AUTOSAR XML (schema 3.1.2)
package /Components/SWC_AdvMinT
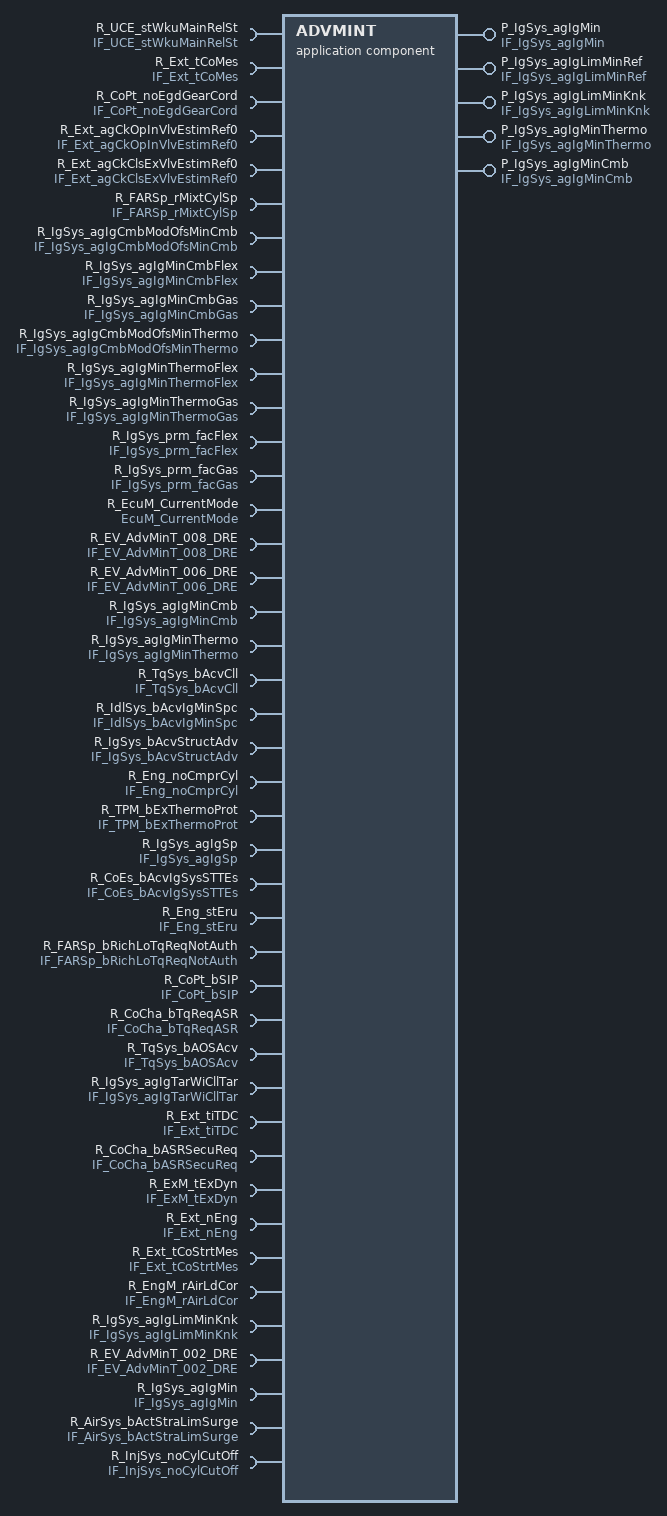
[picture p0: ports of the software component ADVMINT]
  application software component type ADVMINT  # AdvMinT
    require port R_UCE_stWkuMainRelSt: required-interface=IF_UCE_stWkuMainRelSt
    5 x provide port:
      P_IgSys_agIgMin: unqueued-sender-com-spec{data-element=IgSys_agIgMin, can-invalidate=false, init-value=ConstantValue}, provided-interface=IF_IgSys_agIgMin
      P_IgSys_agIgLimMinRef: unqueued-sender-com-spec{data-element=IgSys_agIgLimMinRef, can-invalidate=false, init-value=UInt8InitValue}, provided-interface=IF_IgSys_agIgLimMinRef
      P_IgSys_agIgLimMinKnk: unqueued-sender-com-spec{data-element=IgSys_agIgLimMinKnk, can-invalidate=false, init-value=UInt8InitValue1}, provided-interface=IF_IgSys_agIgLimMinKnk
      P_IgSys_agIgMinThermo: unqueued-sender-com-spec{data-element=IgSys_agIgMinThermo, can-invalidate=false, init-value=UInt8InitValue3}, provided-interface=IF_IgSys_agIgMinThermo
      P_IgSys_agIgMinCmb: unqueued-sender-com-spec{data-element=IgSys_agIgMinCmb, can-invalidate=false, init-value=UInt8InitValue5}, provided-interface=IF_IgSys_agIgMinCmb
    42 x require port:
      R_Ext_tCoMes: unqueued-receiver-com-spec{data-element=Ext_tCoMes, init-value=ConstantValue7, resync-time=0}, required-interface=IF_Ext_tCoMes
      R_CoPt_noEgdGearCord: unqueued-receiver-com-spec{data-element=CoPt_noEgdGearCord, init-value=ConstantValue9, resync-time=0}, required-interface=IF_CoPt_noEgdGearCord
      R_Ext_agCkOpInVlvEstimRef0: unqueued-receiver-com-spec{data-element=Ext_agCkOpInVlvEstimRef0, init-value=ConstantValue11, resync-time=0}, required-interface=IF_Ext_agCkOpInVlvEstimRef0
      R_Ext_agCkClsExVlvEstimRef0: unqueued-receiver-com-spec{data-element=Ext_agCkClsExVlvEstimRef0, init-value=ConstantValue13, resync-time=0}, required-interface=IF_Ext_agCkClsExVlvEstimRef0
      R_FARSp_rMixtCylSp: unqueued-receiver-com-spec{data-element=FARSp_rMixtCylSp, init-value=ConstantValue15, resync-time=0}, required-interface=IF_FARSp_rMixtCylSp
      R_IgSys_agIgCmbModOfsMinCmb: unqueued-receiver-com-spec{data-element=IgSys_agIgCmbModOfsMinCmb, init-value=SInt16InitValue, resync-time=0}, required-interface=IF_IgSys_agIgCmbModOfsMinCmb
      R_IgSys_agIgMinCmbFlex: unqueued-receiver-com-spec{data-element=IgSys_agIgMinCmbFlex, init-value=SInt16InitValue17, resync-time=0}, required-interface=IF_IgSys_agIgMinCmbFlex
      R_IgSys_agIgMinCmbGas: unqueued-receiver-com-spec{data-element=IgSys_agIgMinCmbGas, init-value=SInt16InitValue19, resync-time=0}, required-interface=IF_IgSys_agIgMinCmbGas
      R_IgSys_agIgCmbModOfsMinThermo: unqueued-receiver-com-spec{data-element=IgSys_agIgCmbModOfsMinThermo, init-value=SInt16InitValue21, resync-time=0}, required-interface=IF_IgSys_agIgCmbModOfsMinThermo
      R_IgSys_agIgMinThermoFlex: unqueued-receiver-com-spec{data-element=IgSys_agIgMinThermoFlex, init-value=SInt16InitValue23, resync-time=0}, required-interface=IF_IgSys_agIgMinThermoFlex
      R_IgSys_agIgMinThermoGas: unqueued-receiver-com-spec{data-element=IgSys_agIgMinThermoGas, init-value=SInt16InitValue25, resync-time=0}, required-interface=IF_IgSys_agIgMinThermoGas
      R_IgSys_prm_facFlex: unqueued-receiver-com-spec{data-element=IgSys_prm_facFlex, init-value=ArrayConstantValue, resync-time=0}, required-interface=IF_IgSys_prm_facFlex
      R_IgSys_prm_facGas: unqueued-receiver-com-spec{data-element=IgSys_prm_facGas, init-value=ArrayConstantValue27, resync-time=0}, required-interface=IF_IgSys_prm_facGas
      R_EcuM_CurrentMode: required-interface=EcuM_CurrentMode
      R_EV_AdvMinT_008_DRE: unqueued-receiver-com-spec{data-element=EV_AdvMinT_008_DRE, init-value=UInt8InitValue29, resync-time=0}, required-interface=IF_EV_AdvMinT_008_DRE
      R_EV_AdvMinT_006_DRE: unqueued-receiver-com-spec{data-element=EV_AdvMinT_006_DRE, init-value=UInt8InitValue31, resync-time=0}, required-interface=IF_EV_AdvMinT_006_DRE
      R_IgSys_agIgMinCmb: unqueued-receiver-com-spec{data-element=IgSys_agIgMinCmb, init-value=UInt8InitValue33, resync-time=0}, required-interface=IF_IgSys_agIgMinCmb
      R_IgSys_agIgMinThermo: unqueued-receiver-com-spec{data-element=IgSys_agIgMinThermo, init-value=UInt8InitValue35, resync-time=0}, required-interface=IF_IgSys_agIgMinThermo
      R_TqSys_bAcvCll: unqueued-receiver-com-spec{data-element=TqSys_bAcvCll, init-value=BooleanInitValue, resync-time=0}, required-interface=IF_TqSys_bAcvCll
      R_IdlSys_bAcvIgMinSpc: unqueued-receiver-com-spec{data-element=IdlSys_bAcvIgMinSpc, init-value=BooleanInitValue37, resync-time=0}, required-interface=IF_IdlSys_bAcvIgMinSpc
      R_IgSys_bAcvStructAdv: unqueued-receiver-com-spec{data-element=IgSys_bAcvStructAdv, init-value=ConstantValue39, resync-time=0}, required-interface=IF_IgSys_bAcvStructAdv
      R_Eng_noCmprCyl: unqueued-receiver-com-spec{data-element=Eng_noCmprCyl, init-value=ConstantValue41, resync-time=0}, required-interface=IF_Eng_noCmprCyl
      R_TPM_bExThermoProt: unqueued-receiver-com-spec{data-element=TPM_bExThermoProt, init-value=BooleanInitValue43, resync-time=0}, required-interface=IF_TPM_bExThermoProt
      R_IgSys_agIgSp: unqueued-receiver-com-spec{data-element=IgSys_agIgSp, init-value=ConstantValue45, resync-time=0}, required-interface=IF_IgSys_agIgSp
      R_CoEs_bAcvIgSysSTTEs: unqueued-receiver-com-spec{data-element=CoEs_bAcvIgSysSTTEs, init-value=ConstantValue47, resync-time=0}, required-interface=IF_CoEs_bAcvIgSysSTTEs
      R_Eng_stEru: unqueued-receiver-com-spec{data-element=Eng_stEru, init-value=ConstantValue49, resync-time=0}, required-interface=IF_Eng_stEru
      R_FARSp_bRichLoTqReqNotAuth: unqueued-receiver-com-spec{data-element=FARSp_bRichLoTqReqNotAuth, init-value=BooleanInitValue51, resync-time=0}, required-interface=IF_FARSp_bRichLoTqReqNotAuth
      R_CoPt_bSIP: unqueued-receiver-com-spec{data-element=CoPt_bSIP, init-value=BooleanInitValue53, resync-time=0}, required-interface=IF_CoPt_bSIP
      R_CoCha_bTqReqASR: unqueued-receiver-com-spec{data-element=CoCha_bTqReqASR, init-value=BooleanInitValue55, resync-time=0}, required-interface=IF_CoCha_bTqReqASR
      R_TqSys_bAOSAcv: unqueued-receiver-com-spec{data-element=TqSys_bAOSAcv, init-value=BooleanInitValue57, resync-time=0}, required-interface=IF_TqSys_bAOSAcv
      R_IgSys_agIgTarWiCllTar: unqueued-receiver-com-spec{data-element=IgSys_agIgTarWiCllTar, init-value=ConstantValue59, resync-time=0}, required-interface=IF_IgSys_agIgTarWiCllTar
      R_Ext_tiTDC: unqueued-receiver-com-spec{data-element=Ext_tiTDC, init-value=ConstantValue61, resync-time=0}, required-interface=IF_Ext_tiTDC
      R_CoCha_bASRSecuReq: unqueued-receiver-com-spec{data-element=CoCha_bASRSecuReq, init-value=BooleanInitValue63, resync-time=0}, required-interface=IF_CoCha_bASRSecuReq
      R_ExM_tExDyn: unqueued-receiver-com-spec{data-element=ExM_tExDyn, init-value=UInt16InitValue, resync-time=0}, required-interface=IF_ExM_tExDyn
      R_Ext_nEng: unqueued-receiver-com-spec{data-element=Ext_nEng, init-value=ConstantValue65, resync-time=0}, required-interface=IF_Ext_nEng
      R_Ext_tCoStrtMes: unqueued-receiver-com-spec{data-element=Ext_tCoStrtMes, init-value=SInt16InitValue67, resync-time=0}, required-interface=IF_Ext_tCoStrtMes
      R_EngM_rAirLdCor: unqueued-receiver-com-spec{data-element=EngM_rAirLdCor, init-value=ConstantValue69, resync-time=0}, required-interface=IF_EngM_rAirLdCor
      R_IgSys_agIgLimMinKnk: unqueued-receiver-com-spec{data-element=IgSys_agIgLimMinKnk, init-value=UInt8InitValue71, resync-time=0}, required-interface=IF_IgSys_agIgLimMinKnk
      R_EV_AdvMinT_002_DRE: unqueued-receiver-com-spec{data-element=EV_AdvMinT_002_DRE, init-value=UInt8InitValue73, resync-time=0}, required-interface=IF_EV_AdvMinT_002_DRE
      R_IgSys_agIgMin: unqueued-receiver-com-spec{data-element=IgSys_agIgMin, init-value=ConstantValue, resync-time=0}, required-interface=IF_IgSys_agIgMin
      R_AirSys_bActStraLimSurge: unqueued-receiver-com-spec{data-element=AirSys_bActStraLimSurge, init-value=BooleanInitValue75, resync-time=0}, required-interface=IF_AirSys_bActStraLimSurge
      R_InjSys_noCylCutOff: unqueued-receiver-com-spec{data-element=InjSys_noCylCutOff, init-value=UInt8InitValue77, resync-time=0}, required-interface=IF_InjSys_noCylCutOff
  48 x constant specification:
    ArrayConstantValue
      value:
        array specification ArrayConstantValue: type=rt_Array_UInt8_10_m0
          10 x integer literal, all with type=DT_IgSys_prm_facFlex, value=0:
            Const
            Const{1..9}
    ArrayConstantValue27
      value:
        array specification ArrayConstantValue27: type=rt_Array_UInt8_10_m1
          10 x integer literal, all with type=DT_IgSys_prm_facGas, value=0:
            Const
            Const{1..9}
    BooleanInitValue
      value:
        boolean literal BooleanInitValue: type=DT_TqSys_bAcvCll, value=false
    BooleanInitValue37
      value:
        boolean literal BooleanInitValue37: type=DT_IdlSys_bAcvIgMinSpc, value=false
    BooleanInitValue43
      value:
        boolean literal BooleanInitValue43: type=DT_TPM_bExThermoProt, value=false
    BooleanInitValue51
      value:
        boolean literal BooleanInitValue51: type=DT_FARSp_bRichLoTqReqNotAuth, value=false
    BooleanInitValue53
      value:
        boolean literal BooleanInitValue53: type=DT_CoPt_bSIP, value=false
    BooleanInitValue55
      value:
        boolean literal BooleanInitValue55: type=DT_CoCha_bTqReqASR, value=false
    BooleanInitValue57
      value:
        boolean literal BooleanInitValue57: type=DT_TqSys_bAOSAcv, value=false
    BooleanInitValue63
      value:
        boolean literal BooleanInitValue63: type=DT_CoCha_bASRSecuReq, value=false
    BooleanInitValue75
      value:
        boolean literal BooleanInitValue75: type=DT_AirSys_bActStraLimSurge, value=false
    ConstantValue
      value:
        integer literal ConstantValue: type=DT_IgSys_agIgMin, value=0
    ConstantValue11
      value:
        integer literal ConstantValue11: type=DT_Ext_agCkOpInVlvEstimRef0, value=-1024
    ConstantValue13
      value:
        integer literal ConstantValue13: type=DT_Ext_agCkClsExVlvEstimRef0, value=-1024
    ConstantValue15
      value:
        integer literal ConstantValue15: type=DT_FARSp_rMixtCylSp, value=4096
    ConstantValue39
      value:
        boolean literal ConstantValue39: type=DT_IgSys_bAcvStructAdv, value=false
    ConstantValue41
      value:
        integer literal ConstantValue41: type=DT_Eng_noCmprCyl, value=1
    ConstantValue45
      value:
        integer literal ConstantValue45: type=DT_IgSys_agIgSp, value=96
    ConstantValue47
      value:
        boolean literal ConstantValue47: type=DT_CoEs_bAcvIgSysSTTEs, value=false
    ConstantValue49
      value:
        integer literal ConstantValue49: type=DT_Eng_stEru, value=1
    ConstantValue59
      value:
        integer literal ConstantValue59: type=DT_IgSys_agIgTarWiCllTar, value=150
    ConstantValue61
      value:
        integer literal ConstantValue61: type=DT_Ext_tiTDC, value=100
    ConstantValue65
      value:
        integer literal ConstantValue65: type=DT_Ext_nEng, value=0
    ConstantValue69
      value:
        integer literal ConstantValue69: type=DT_EngM_rAirLdCor, value=0
    ConstantValue7
      value:
        integer literal ConstantValue7: type=DT_Ext_tCoMes, value=20
    ConstantValue9
      value:
        integer literal ConstantValue9: type=DT_CoPt_noEgdGearCord, value=0
    InitValue_UInt8_0
      value:
        integer literal InitValue_UInt8_0: type=DT_IgSys_agIgMinDriv_irv, value=0
    InitValue_UInt8_079
      value:
        integer literal InitValue_UInt8_079: type=DT_IgSys_ctLimAdvReact_irv, value=0
    InitValue_UInt8_081
      value:
        integer literal InitValue_UInt8_081: type=DT_IgSys_agIgMinStrt_irv, value=0
    SInt16InitValue
      value:
        integer literal SInt16InitValue: type=DT_IgSys_agIgCmbModOfsMinCmb, value=0
    SInt16InitValue17
      value:
        integer literal SInt16InitValue17: type=DT_IgSys_agIgMinCmbFlex, value=0
    SInt16InitValue19
      value:
        integer literal SInt16InitValue19: type=DT_IgSys_agIgMinCmbGas, value=0
    SInt16InitValue21
      value:
        integer literal SInt16InitValue21: type=DT_IgSys_agIgCmbModOfsMinThermo, value=0
    SInt16InitValue23
      value:
        integer literal SInt16InitValue23: type=DT_IgSys_agIgMinThermoFlex, value=0
    SInt16InitValue25
      value:
        integer literal SInt16InitValue25: type=DT_IgSys_agIgMinThermoGas, value=0
    SInt16InitValue67
      value:
        integer literal SInt16InitValue67: type=DT_Ext_tCoStrtMes, value=-40
    UInt16InitValue
      value:
        integer literal UInt16InitValue: type=DT_ExM_tExDyn, value=0
    UInt8InitValue
      value:
        integer literal UInt8InitValue: type=DT_IgSys_agIgLimMinRef, value=0
    UInt8InitValue1
      value:
        integer literal UInt8InitValue1: type=DT_IgSys_agIgLimMinKnk, value=0
    UInt8InitValue29
      value:
        integer literal UInt8InitValue29: type=DT_EV_AdvMinT_008_DRE, value=0
    UInt8InitValue3
      value:
        integer literal UInt8InitValue3: type=DT_IgSys_agIgMinThermo, value=96
    UInt8InitValue31
      value:
        integer literal UInt8InitValue31: type=DT_EV_AdvMinT_006_DRE, value=0
    UInt8InitValue33
      value:
        integer literal UInt8InitValue33: type=DT_IgSys_agIgMinCmb, value=96
    UInt8InitValue35
      value:
        integer literal UInt8InitValue35: type=DT_IgSys_agIgMinThermo, value=96
    UInt8InitValue5
      value:
        integer literal UInt8InitValue5: type=DT_IgSys_agIgMinCmb, value=96
    UInt8InitValue71
      value:
        integer literal UInt8InitValue71: type=DT_IgSys_agIgLimMinKnk, value=0
    UInt8InitValue73
      value:
        integer literal UInt8InitValue73: type=DT_EV_AdvMinT_002_DRE, value=0
    UInt8InitValue77
      value:
        integer literal UInt8InitValue77: type=DT_InjSys_noCylCutOff, value=0
  internal behavior IB_AdvMinT: component=ADVMINT
    mode switch event EV_AdvMinT_005_MSE: start-on-event=RE_AdvMinT_005_MSE, activation=ENTRY, mode=R_EcuM_CurrentMode.currentMode.RUN
    mode switch event EV_AdvMinT_001_MSE: start-on-event=RE_AdvMinT_001_MSE, activation=ENTRY, mode=R_EcuM_CurrentMode.currentMode.RUN
    data received event EV_AdvMinT_002_DRE: mode-dependency=dependent-on-mode=[R_UCE_stWkuMainRelSt.RCD_stWkuMainRelSt.PreMainWakeUp, R_UCE_stWkuMainRelSt.RCD_stWkuMainRelSt.PostMainWakeUp, R_UCE_stWkuMainRelSt.RCD_stWkuMainRelSt.Invalid], start-on-event=RE_AdvMinT_002_DRE, data=R_EV_AdvMinT_002_DRE.EV_AdvMinT_002_DRE
    data received event EV_AdvMinT_006_DRE: mode-dependency=dependent-on-mode=[R_UCE_stWkuMainRelSt.RCD_stWkuMainRelSt.PreMainWakeUp, R_UCE_stWkuMainRelSt.RCD_stWkuMainRelSt.PostMainWakeUp, R_UCE_stWkuMainRelSt.RCD_stWkuMainRelSt.Invalid], start-on-event=RE_AdvMinT_006_DRE, data=R_EV_AdvMinT_006_DRE.EV_AdvMinT_006_DRE
    data received event EV_AdvMinT_008_DRE: mode-dependency=dependent-on-mode=[R_UCE_stWkuMainRelSt.RCD_stWkuMainRelSt.PreMainWakeUp, R_UCE_stWkuMainRelSt.RCD_stWkuMainRelSt.PostMainWakeUp, R_UCE_stWkuMainRelSt.RCD_stWkuMainRelSt.Invalid], start-on-event=RE_AdvMinT_008_DRE, data=R_EV_AdvMinT_008_DRE.EV_AdvMinT_008_DRE
    inter runnable variable IgSys_agIgMinStrt_irv: sw-calibration-access=READ-WRITE, type=DT_IgSys_agIgMinStrt_irv, communication-approach=EXPLICIT, init-value=InitValue_UInt8_081
    inter runnable variable IgSys_agIgMinDriv_irv: sw-calibration-access=READ-WRITE, type=DT_IgSys_agIgMinDriv_irv, communication-approach=EXPLICIT, init-value=InitValue_UInt8_0
    inter runnable variable IgSys_ctLimAdvReact_irv: sw-calibration-access=READ-WRITE, type=DT_IgSys_ctLimAdvReact_irv, communication-approach=EXPLICIT, init-value=InitValue_UInt8_079
    5 x runnable:
      RE_AdvMinT_008_DRE: written-variable=IgSys_ctLimAdvReact_irv
        data receive point dr_EV_AdvMinT_008_DRE: data-element=R_EV_AdvMinT_008_DRE.EV_AdvMinT_008_DRE
        data receive point dr_CoPt_noEgdGearCord: data-element=R_CoPt_noEgdGearCord.CoPt_noEgdGearCord
      RE_AdvMinT_002_DRE: read-variable=[IgSys_agIgMinDriv_irv, IgSys_agIgMinStrt_irv]
        26 x data receive point:
          dr_TPM_bExThermoProt: data-element=R_TPM_bExThermoProt.TPM_bExThermoProt
          dr_InjSys_noCylCutOff: data-element=R_InjSys_noCylCutOff.InjSys_noCylCutOff
          dr_IgSys_agIgTarWiCllTar: data-element=R_IgSys_agIgTarWiCllTar.IgSys_agIgTarWiCllTar
          dr_IgSys_agIgMin: data-element=R_IgSys_agIgMin.IgSys_agIgMin
          dr_IgSys_agIgLimMinKnk: data-element=R_IgSys_agIgLimMinKnk.IgSys_agIgLimMinKnk
          dr_TqSys_bAcvCll: data-element=R_TqSys_bAcvCll.TqSys_bAcvCll
          dr_Ext_nEng: data-element=R_Ext_nEng.Ext_nEng
          dr_CoCha_bASRSecuReq: data-element=R_CoCha_bASRSecuReq.CoCha_bASRSecuReq
          dr_CoPt_bSIP: data-element=R_CoPt_bSIP.CoPt_bSIP
          dr_Ext_tiTDC: data-element=R_Ext_tiTDC.Ext_tiTDC
          dr_CoCha_bTqReqASR: data-element=R_CoCha_bTqReqASR.CoCha_bTqReqASR
          dr_IgSys_agIgMinCmb: data-element=R_IgSys_agIgMinCmb.IgSys_agIgMinCmb
          dr_CoEs_bAcvIgSysSTTEs: data-element=R_CoEs_bAcvIgSysSTTEs.CoEs_bAcvIgSysSTTEs
          dr_TqSys_bAOSAcv: data-element=R_TqSys_bAOSAcv.TqSys_bAOSAcv
          dr_Ext_tCoStrtMes: data-element=R_Ext_tCoStrtMes.Ext_tCoStrtMes
          dr_ExM_tExDyn: data-element=R_ExM_tExDyn.ExM_tExDyn
          dr_IgSys_agIgSp: data-element=R_IgSys_agIgSp.IgSys_agIgSp
          dr_Eng_noCmprCyl: data-element=R_Eng_noCmprCyl.Eng_noCmprCyl
          dr_IdlSys_bAcvIgMinSpc: data-element=R_IdlSys_bAcvIgMinSpc.IdlSys_bAcvIgMinSpc
          dr_Eng_stEru: data-element=R_Eng_stEru.Eng_stEru
          dr_IgSys_bAcvStructAdv: data-element=R_IgSys_bAcvStructAdv.IgSys_bAcvStructAdv
          dr_IgSys_agIgMinThermo: data-element=R_IgSys_agIgMinThermo.IgSys_agIgMinThermo
          dr_AirSys_bActStraLimSurge: data-element=R_AirSys_bActStraLimSurge.AirSys_bActStraLimSurge
          dr_EV_AdvMinT_002_DRE: data-element=R_EV_AdvMinT_002_DRE.EV_AdvMinT_002_DRE
          dr_FARSp_bRichLoTqReqNotAuth: data-element=R_FARSp_bRichLoTqReqNotAuth.FARSp_bRichLoTqReqNotAuth
          dr_EngM_rAirLdCor: data-element=R_EngM_rAirLdCor.EngM_rAirLdCor
      RE_AdvMinT_001_MSE
        data send point ds_IgSys_agIgMin: data-element=P_IgSys_agIgMin.IgSys_agIgMin
      RE_AdvMinT_005_MSE: written-variable=[IgSys_agIgMinStrt_irv, IgSys_ctLimAdvReact_irv, IgSys_agIgMinDriv_irv]
        4 x data send point:
          ds_IgSys_agIgMinThermo: data-element=P_IgSys_agIgMinThermo.IgSys_agIgMinThermo
          ds_IgSys_agIgMinCmb: data-element=P_IgSys_agIgMinCmb.IgSys_agIgMinCmb
          ds_IgSys_agIgLimMinKnk: data-element=P_IgSys_agIgLimMinKnk.IgSys_agIgLimMinKnk
          ds_IgSys_agIgLimMinRef: data-element=P_IgSys_agIgLimMinRef.IgSys_agIgLimMinRef
      RE_AdvMinT_006_DRE: read-variable=IgSys_ctLimAdvReact_irv, written-variable=[IgSys_ctLimAdvReact_irv, IgSys_agIgMinStrt_irv, IgSys_agIgMinDriv_irv]
        16 x data receive point:
          dr_IgSys_agIgCmbModOfsMinThermo: data-element=R_IgSys_agIgCmbModOfsMinThermo.IgSys_agIgCmbModOfsMinThermo
          dr_Ext_tCoStrtMes: data-element=R_Ext_tCoStrtMes.Ext_tCoStrtMes
          dr_Ext_tCoMes: data-element=R_Ext_tCoMes.Ext_tCoMes
          dr_IgSys_prm_facGas: data-element=R_IgSys_prm_facGas.IgSys_prm_facGas
          dr_Ext_agCkClsExVlvEstimRef0: data-element=R_Ext_agCkClsExVlvEstimRef0.Ext_agCkClsExVlvEstimRef0
          dr_IgSys_agIgMinThermoFlex: data-element=R_IgSys_agIgMinThermoFlex.IgSys_agIgMinThermoFlex
          dr_FARSp_rMixtCylSp: data-element=R_FARSp_rMixtCylSp.FARSp_rMixtCylSp
          dr_IgSys_agIgMinThermoGas: data-element=R_IgSys_agIgMinThermoGas.IgSys_agIgMinThermoGas
          dr_Ext_agCkOpInVlvEstimRef0: data-element=R_Ext_agCkOpInVlvEstimRef0.Ext_agCkOpInVlvEstimRef0
          dr_Ext_nEng: data-element=R_Ext_nEng.Ext_nEng
          dr_IgSys_prm_facFlex: data-element=R_IgSys_prm_facFlex.IgSys_prm_facFlex
          dr_EV_AdvMinT_006_DRE: data-element=R_EV_AdvMinT_006_DRE.EV_AdvMinT_006_DRE
          dr_IgSys_agIgMinCmbGas: data-element=R_IgSys_agIgMinCmbGas.IgSys_agIgMinCmbGas
          dr_IgSys_agIgMinCmbFlex: data-element=R_IgSys_agIgMinCmbFlex.IgSys_agIgMinCmbFlex
          dr_IgSys_agIgCmbModOfsMinCmb: data-element=R_IgSys_agIgCmbModOfsMinCmb.IgSys_agIgCmbModOfsMinCmb
          dr_EngM_rAirLdCor: data-element=R_EngM_rAirLdCor.EngM_rAirLdCor
        4 x data send point:
          ds_IgSys_agIgLimMinKnk: data-element=P_IgSys_agIgLimMinKnk.IgSys_agIgLimMinKnk
          ds_IgSys_agIgMinCmb: data-element=P_IgSys_agIgMinCmb.IgSys_agIgMinCmb
          ds_IgSys_agIgLimMinRef: data-element=P_IgSys_agIgLimMinRef.IgSys_agIgLimMinRef
          ds_IgSys_agIgMinThermo: data-element=P_IgSys_agIgMinThermo.IgSys_agIgMinThermo
  swc implementation Imp_AdvMinT: code-generator=Real-Time Workshop Embedded Coder 5.5 (R2010a) 25-Jan-2010, programming-language=C, behavior=IB_AdvMinT
    code-descriptors:
      code CodeDescriptor: type=SRC
        10 x xfile:
          AdvMinT_data_c: url=AdvMinT_data.c
          AdvMinT_c: url=AdvMinT.c
          AdvMinT_import_h: url=AdvMinT_import.h
          AdvMinT_Def_c: url=AdvMinT_Def.c
          AdvMinT_types_h: url=AdvMinT_types.h
          AdvMinT_private_h: url=AdvMinT_private.h
          AdvMinT_h: url=AdvMinT.h
          AdvMinT_Version_c: url=AdvMinT_Version.c
          AdvMinT_MemMap_h: url=AdvMinT_MemMap.h
          AdvMinT_Version_h: url=AdvMinT_Version.h
package /Components/SWC_AdvMinT/AdvMinT_IRVDatatypes
  integer type DT_IgSys_agIgMinDriv_irv: base-type=uint8, lower-limit=0, upper-limit=255
  integer type DT_IgSys_agIgMinStrt_irv: base-type=uint8, lower-limit=0, upper-limit=255
  integer type DT_IgSys_ctLimAdvReact_irv: base-type=uint8, lower-limit=0, upper-limit=255
